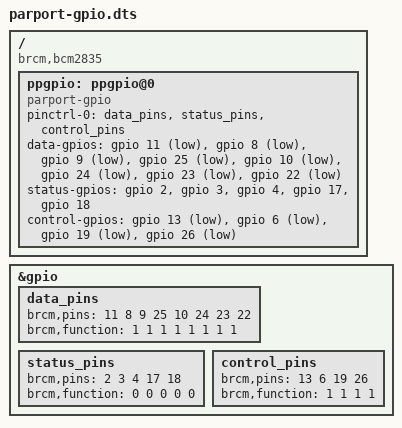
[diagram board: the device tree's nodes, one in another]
/dts-v1/;
/plugin/;

/ {
	compatible = "brcm,bcm2835", "brcm,bcm2708", "brcm,bcm2709";

	fragment@0 {
		target = <&gpio>;
		__overlay__ {
			data_pins: data_pins {
				brcm,pins =     <11  8  9 25 10 24 23 22>;
				brcm,function = < 1  1  1  1  1  1  1  1>; // out
			};
			status_pins: status_pins {
				brcm,pins =     < 2  3  4 17 18>;
				brcm,function = < 0  0  0  0  0>; // in
			};
			control_pins: control_pins {
				brcm,pins =     <13  6 19 26>;
				brcm,function = < 1  1  1  1>; // out
			};
		};
	};

	fragment@1 {
		target-path = "/";
		__overlay__ {
			ppgpio: ppgpio@0 {
				compatible = "parport-gpio";
				pinctrl-names = "default";
				pinctrl-0 = <&data_pins>,
	 				    <&status_pins>,
					    <&control_pins>;
				data-gpios = <&gpio 11 1>,
					     <&gpio 8 1>,
					     <&gpio 9 1>,
					     <&gpio 25 1>,
					     <&gpio 10 1>,
					     <&gpio 24 1>,
					     <&gpio 23 1>,
					     <&gpio 22 1>;
				status-gpios = <&gpio 2 0>,
					       <&gpio 3 0>,
					       <&gpio 4 0>,
					       <&gpio 17 0>,
					       <&gpio 18 0>;
				control-gpios = <&gpio 13 1>,
					        <&gpio 6 1>,
					        <&gpio 19 1>,
					        <&gpio 26 1>;
			};
		};
	};
};
